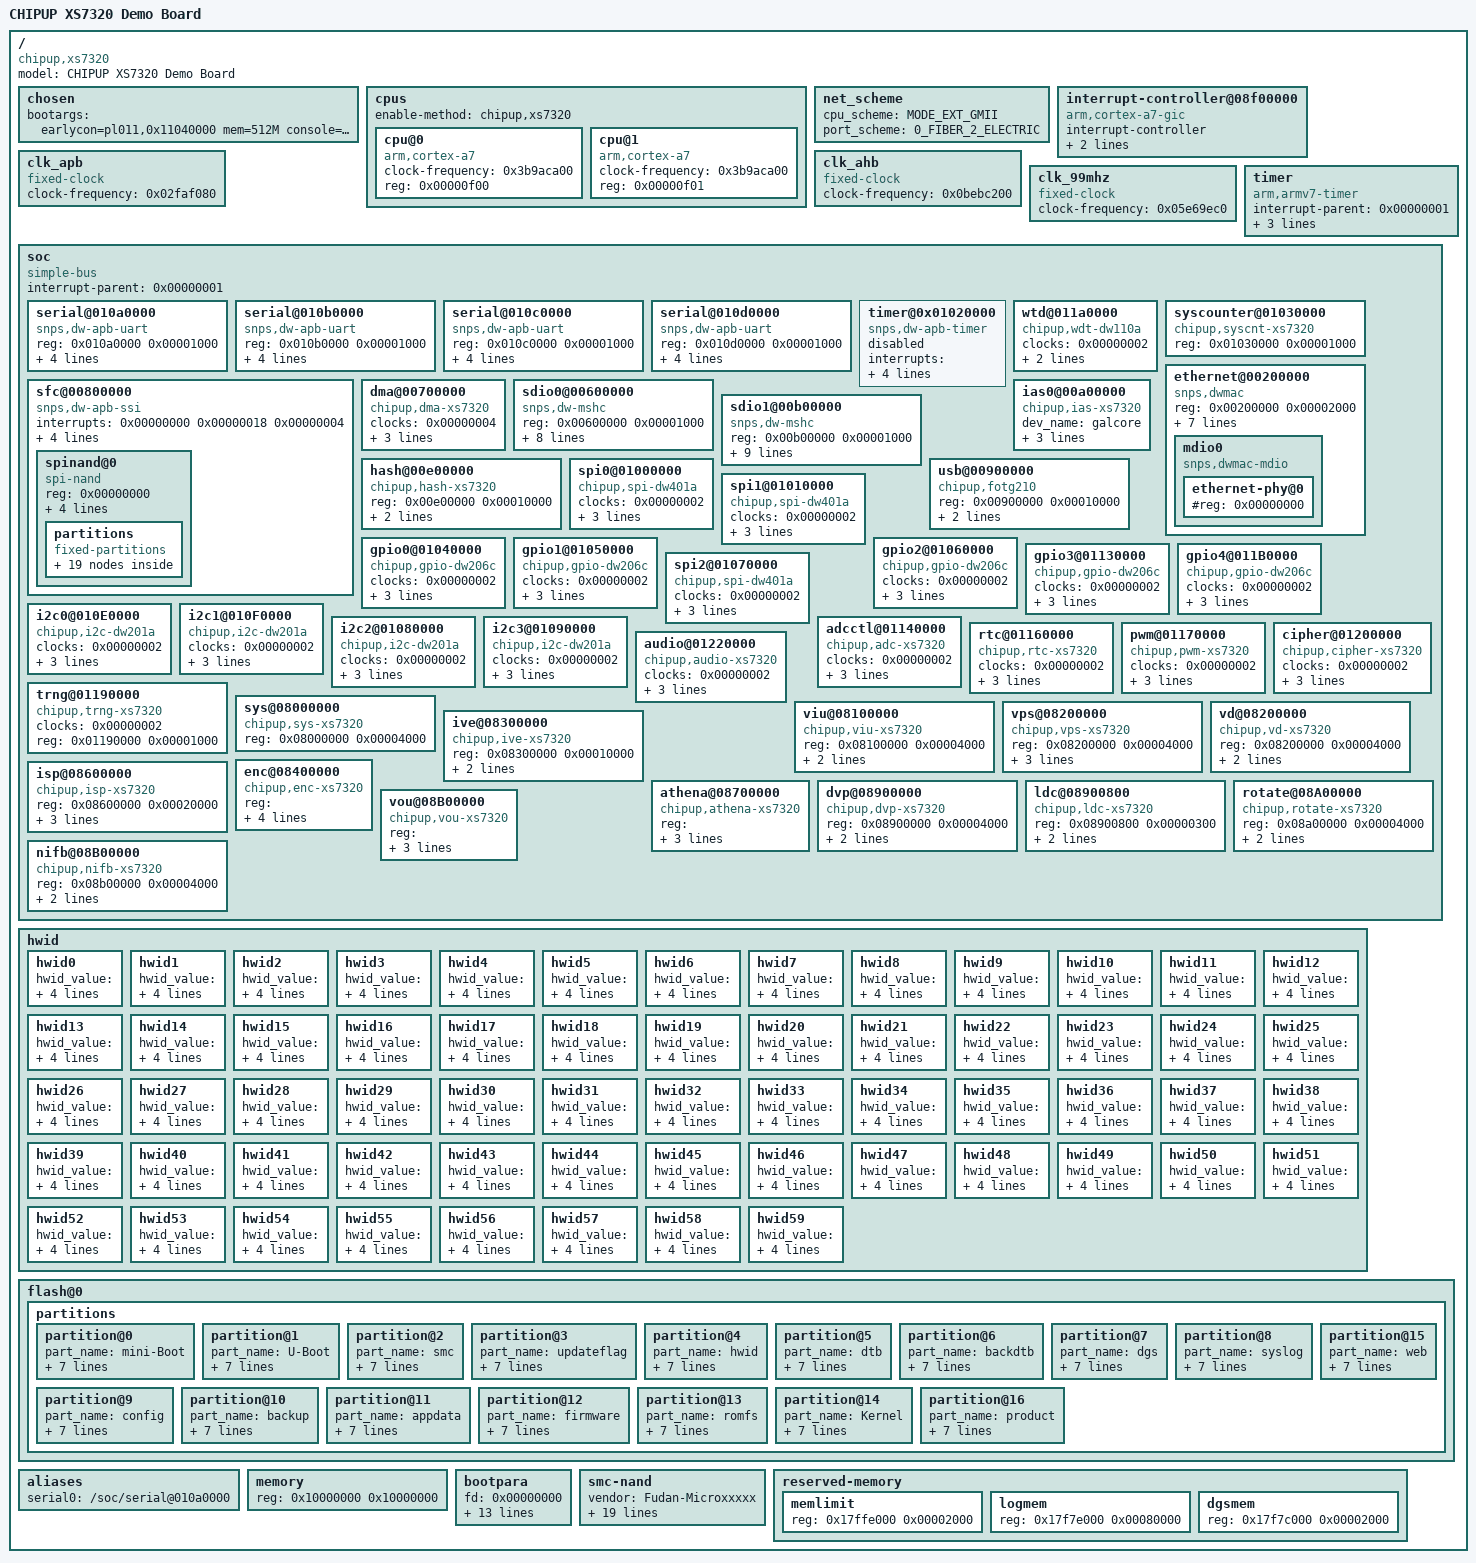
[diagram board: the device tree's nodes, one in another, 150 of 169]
/dts-v1/;
// magic:		0xd00dfeed
// totalsize:		0x86c5 (34501)
// off_dt_struct:	0x38
// off_dt_strings:	0x8318
// off_mem_rsvmap:	0x28
// version:		17
// last_comp_version:	16
// boot_cpuid_phys:	0x0
// size_dt_strings:	0x3ad
// size_dt_struct:	0x82e0

/ {
    #address-cells = <0x00000001>;
    #size-cells = <0x00000001>;
    model = "CHIPUP XS7320 Demo Board";
    compatible = "chipup,xs7320";
    chosen {
        bootargs = "earlycon=pl011,0x11040000 mem=512M console=ttyAMA0,115200 clk_ignore_unused initrd=0x00000000,0x00000000 root=/dev/mtdblock2 rootfstype=yaffs2 rw mtdparts=hinand:1M(boot),9M(kernel),32M(rootfs),1M(this_bootargs_string_is_reserved_for_bootargs_form_uboot!!!_it_must_be_longer_than_bootargs_form_uboot!!!_this_bootargs_string_is_reserved_for_bootargs_form_uboot!!!_it_must_be_longer_than_bootargs_form_uboot!!!_this_bootargs_string_is_reserved_for_bootargs_form_uboot!!!_it_must_be_longer_than_bootargs_form_uboot!!!_this_bootargs_string_is_reserved_for_bootargs_form_uboot!!!_it_must_be_longer_than_bootargs_form_uboot!!!_this_bootargs_string_is_reserved_for_bootargs_form_uboot!!!_it_must_be_longer_than_bootargs_form_uboot!!!)";
    };
    cpus {
        #address-cells = <0x00000001>;
        #size-cells = <0x00000000>;
        enable-method = "chipup,xs7320";
        cpu@0 {
            device_type = "cpu";
            compatible = "arm,cortex-a7";
            clock-frequency = <0x3b9aca00>;
            reg = <0x00000f00>;
        };
        cpu@1 {
            device_type = "cpu";
            compatible = "arm,cortex-a7";
            clock-frequency = <0x3b9aca00>;
            reg = <0x00000f01>;
        };
    };
    net_scheme {
        cpu_scheme = "MODE_EXT_GMII";
        port_scheme = "0_FIBER_2_ELECTRIC";
    };
    interrupt-controller@08f00000 {
        compatible = "arm,cortex-a7-gic";
        #interrupt-cells = <0x00000003>;
        interrupt-controller;
        reg = <0x08f01000 0x00001000 0x08f02000 0x00001000>;
        phandle = <0x00000001>;
    };
    clk_apb {
        compatible = "fixed-clock";
        #clock-cells = <0x00000000>;
        clock-frequency = <0x02faf080>;
        phandle = <0x00000002>;
    };
    clk_ahb {
        compatible = "fixed-clock";
        #clock-cells = <0x00000000>;
        clock-frequency = <0x0bebc200>;
        phandle = <0x00000004>;
    };
    clk_99mhz {
        compatible = "fixed-clock";
        #clock-cells = <0x00000000>;
        clock-frequency = <0x05e69ec0>;
        phandle = <0x00000005>;
    };
    timer {
        compatible = "arm,armv7-timer";
        interrupt-parent = <0x00000001>;
        clock-frequency = <0x016e3600>;
        arm,cpu-registers-not-fw-configured;
        interrupts = <0x00000001 0x0000000d 0x00000004>;
        status = "okay";
    };
    soc {
        #address-cells = <0x00000001>;
        #size-cells = <0x00000001>;
        compatible = "simple-bus";
        interrupt-parent = <0x00000001>;
        ranges;
        serial@010a0000 {
            compatible = "snps,dw-apb-uart";
            reg = <0x010a0000 0x00001000>;
            interrupts = <0x00000000 0x0000000c 0x00000004>;
            clocks = <0x00000002>;
            clock-names = "apb_pclk";
            reg-shift = <0x00000002>;
            reg-io-width = <0x00000004>;
            status = "okay";
        };
        serial@010b0000 {
            compatible = "snps,dw-apb-uart";
            reg = <0x010b0000 0x00001000>;
            interrupts = <0x00000000 0x0000000d 0x00000004>;
            clocks = <0x00000002>;
            clock-names = "apb_pclk";
            reg-shift = <0x00000002>;
            reg-io-width = <0x00000004>;
            status = "okay";
        };
        serial@010c0000 {
            compatible = "snps,dw-apb-uart";
            reg = <0x010c0000 0x00001000>;
            interrupts = <0x00000000 0x0000000e 0x00000004>;
            clocks = <0x00000002>;
            clock-names = "apb_pclk";
            reg-shift = <0x00000002>;
            reg-io-width = <0x00000004>;
            status = "okay";
        };
        serial@010d0000 {
            compatible = "snps,dw-apb-uart";
            reg = <0x010d0000 0x00001000>;
            interrupts = <0x00000000 0x0000000a 0x00000004>;
            clocks = <0x00000002>;
            clock-names = "apb_pclk";
            reg-shift = <0x00000002>;
            reg-io-width = <0x00000004>;
            status = "okay";
        };
        timer@0x01020000 {
            compatible = "snps,dw-apb-timer";
            interrupts = <0x00000000 0x00000001 0x00000004 0x00000000 0x00000002 0x00000004 0x00000000 0x00000003 0x00000004 0x00000000 0x00000004 0x00000004>;
            reg = <0x01020000 0x00001000>;
            clocks = <0x00000002>;
            clock-names = "apb_pclk";
            clock-frequency = <0x02faf080>;
            status = "disable";
        };
        wtd@011a0000 {
            compatible = "chipup,wdt-dw110a";
            clocks = <0x00000002>;
            reg = <0x011a0000 0x00001000>;
            interrupts = <0x00000000 0x00000027 0x00000004>;
        };
        syscounter@01030000 {
            compatible = "chipup,syscnt-xs7320";
            reg = <0x01030000 0x00001000>;
        };
        sfc@00800000 {
            compatible = "snps,dw-apb-ssi";
            interrupts = <0x00000000 0x00000018 0x00000004>;
            reg = <0x00800000 0x00010000>;
            reg-io-width = <0x00000004>;
            num-cs = <0x00000001>;
            clocks = <0x00000004>;
            #address-cells = <0x00000001>;
            #size-cells = <0x00000000>;
            status = "okay";
            spinand@0 {
                compatible = "spi-nand";
                reg = <0x00000000>;
                spi-max-frequency = <0x02faf080>;
                max-fifo-len = <0x00000080>;
                spi-rx-bus-width = <0x00000004>;
                spi-tx-bus-width = <0x00000001>;
                partitions {
                    compatible = "fixed-partitions";
                    #address-cells = <0x00000001>;
                    #size-cells = <0x00000001>;
                    partition@0 {
                        label = "mini-Boot";
                        reg = <0x00000000 0x00100000>;
                    };
                    partition@100000 {
                        label = "U-Boot";
                        reg = <0x00100000 0x00200000>;
                    };
                    partition@00300000 {
                        label = "updateflag";
                        reg = <0x00300000 0x00100000>;
                    };
                    partition@00400000 {
                        label = "hwid";
                        reg = <0x00400000 0x00100000>;
                    };
                    partition@00500000 {
                        label = "dtb";
                        reg = <0x00500000 0x00100000>;
                    };
                    partition@00600000 {
                        label = "backdtb";
                        reg = <0x00600000 0x00100000>;
                    };
                    partition@00700000 {
                        label = "dgs";
                        reg = <0x00700000 0x00100000>;
                    };
                    partition@00800000 {
                        label = "syslog";
                        reg = <0x00800000 0x00400000>;
                    };
                    partition@00C00000 {
                        label = "config";
                        reg = <0x00c00000 0x00400000>;
                    };
                    partition@01000000 {
                        label = "backup";
                        reg = <0x01000000 0x00400000>;
                    };
                    partition@01400000 {
                        label = "appdata";
                        reg = <0x01400000 0x00600000>;
                    };
                    partition@01A00000 {
                        label = "firmware";
                        reg = <0x01a00000 0x00400000>;
                    };
                    partition@02200000 {
                        label = "romfs";
                        reg = <0x01e00000 0x01b00000>;
                    };
                    partition@03D00000 {
                        label = "Kernel";
                        reg = <0x03900000 0x00d00000>;
                    };
                    partition@04800000 {
                        label = "web";
                        reg = <0x04600000 0x00c00000>;
                    };
                    partition@05400000 {
                        label = "product";
                        reg = <0x05200000 0x00300000>;
                    };
                    partition@05700000 {
                        label = "backromfs";
                        reg = <0x05500000 0x01b00000>;
                    };
                    partition@07200000 {
                        label = "backkernel";
                        reg = <0x07000000 0x00d00000>;
                    };
                    partition@07D00000 {
                        label = "backproduct";
                        reg = <0x07d00000 0x00300000>;
                    };
                };
            };
        };
        ethernet@00200000 {
            compatible = "snps,dwmac";
            reg = <0x00200000 0x00002000>;
            interrupt-parent = <0x00000001>;
            interrupts = <0x00000000 0x0000001e 0x00000004>;
            interrupt-names = "macirq";
            clocks = <0x00000004>;
            clock-names = "ni-gmac";
            snps,pbl = <0x00000002>;
            snps,fixed-burst;
            phy-mode = "mii";
            phy-handle = <0x00000003>;
            mdio0 {
                #address-cells = <0x00000001>;
                #size-cells = <0x00000000>;
                compatible = "snps,dwmac-mdio";
                ethernet-phy@0 {
                    #reg = <0x00000000>;
                    phandle = <0x00000003>;
                };
            };
        };
        dma@00700000 {
            compatible = "chipup,dma-xs7320";
            clocks = <0x00000004>;
            reg = <0x00700000 0x00001000>;
            interrupts = <0x00000000 0x0000001d 0x00000004>;
            interrupt-parent = <0x00000001>;
        };
        sdio0@00600000 {
            compatible = "snps,dw-mshc";
            reg = <0x00600000 0x00001000>;
            interrupts = <0x00000000 0x00000014 0x00000004>;
            interrupt-parent = <0x00000001>;
            clocks = <0x00000005 0x00000005>;
            clock-names = "biu", "ciu";
            max-frequency = <0x02faf080>;
            non-removable = "true";
            cap-mmc-highspeed = "true";
            fifo-depth = <0x00000200>;
            bus-width = <0x00000008>;
        };
        ias0@00a00000 {
            compatible = "chipup,ias-xs7320";
            dev_name = "galcore";
            status = "okay";
            reg = <0x00a00000 0x00010000>;
            interrupts = <0x00000000 0x0000002a 0x00000004>;
            interrupt-parent = <0x00000001>;
        };
        sdio1@00b00000 {
            compatible = "snps,dw-mshc";
            reg = <0x00b00000 0x00001000>;
            interrupts = <0x00000000 0x00000015 0x00000004>;
            interrupt-parent = <0x00000001>;
            clocks = <0x00000005 0x00000005>;
            clock-names = "biu", "ciu";
            max-frequency = <0x02faf080>;
            broken-cd = "true";
            cap-sd-highspeed = "true";
            fifo-depth = <0x00000200>;
            bus-width = <0x00000004>;
            pwr-gpio = <0x00000065>;
        };
        hash@00e00000 {
            compatible = "chipup,hash-xs7320";
            reg = <0x00e00000 0x00010000>;
            interrupts = <0x00000000 0x0000002f 0x00000004>;
            interrupt-parent = <0x00000001>;
        };
        usb@00900000 {
            compatible = "chipup,fotg210";
            reg = <0x00900000 0x00010000>;
            interrupts = <0x00000000 0x00000019 0x00000004>;
            interrupt-parent = <0x00000001>;
        };
        spi0@01000000 {
            compatible = "chipup,spi-dw401a";
            clocks = <0x00000002>;
            reg = <0x01000000 0x00001000>;
            interrupts = <0x00000000 0x00000010 0x00000004>;
            interrupt-parent = <0x00000001>;
        };
        spi1@01010000 {
            compatible = "chipup,spi-dw401a";
            clocks = <0x00000002>;
            reg = <0x01010000 0x00001000>;
            interrupts = <0x00000000 0x00000011 0x00000004>;
            interrupt-parent = <0x00000001>;
        };
        gpio0@01040000 {
            compatible = "chipup,gpio-dw206c";
            clocks = <0x00000002>;
            reg = <0x01040000 0x00001000>;
            interrupts = <0x00000000 0x0000000f 0x00000004>;
            interrupt-parent = <0x00000001>;
        };
        gpio1@01050000 {
            compatible = "chipup,gpio-dw206c";
            clocks = <0x00000002>;
            reg = <0x01050000 0x00001000>;
            interrupts = <0x00000000 0x00000013 0x00000004>;
            interrupt-parent = <0x00000001>;
        };
        gpio2@01060000 {
            compatible = "chipup,gpio-dw206c";
            clocks = <0x00000002>;
            reg = <0x01060000 0x00001000>;
            interrupts = <0x00000000 0x00000006 0x00000004>;
            interrupt-parent = <0x00000001>;
        };
        gpio3@01130000 {
            compatible = "chipup,gpio-dw206c";
            clocks = <0x00000002>;
            reg = <0x01130000 0x00001000>;
            interrupts = <0x00000000 0x00000034 0x00000004>;
            interrupt-parent = <0x00000001>;
        };
        gpio4@011B0000 {
            compatible = "chipup,gpio-dw206c";
            clocks = <0x00000002>;
            reg = <0x011b0000 0x00001000>;
            interrupts = <0x00000000 0x0000003d 0x00000004>;
            interrupt-parent = <0x00000001>;
        };
        spi2@01070000 {
            compatible = "chipup,spi-dw401a";
            clocks = <0x00000002>;
            reg = <0x01070000 0x00001000>;
            interrupts = <0x00000000 0x00000016 0x00000004>;
            interrupt-parent = <0x00000001>;
        };
        i2c0@010E0000 {
            compatible = "chipup,i2c-dw201a";
            clocks = <0x00000002>;
            reg = <0x010e0000 0x00001000>;
            interrupts = <0x00000000 0x00000007 0x00000004>;
            interrupt-parent = <0x00000001>;
        };
        i2c1@010F0000 {
            compatible = "chipup,i2c-dw201a";
            clocks = <0x00000002>;
            reg = <0x010f0000 0x00001000>;
            interrupts = <0x00000000 0x00000008 0x00000004>;
            interrupt-parent = <0x00000001>;
        };
        i2c2@01080000 {
            compatible = "chipup,i2c-dw201a";
            clocks = <0x00000002>;
            reg = <0x01080000 0x00001000>;
            interrupts = <0x00000000 0x00000009 0x00000004>;
            interrupt-parent = <0x00000001>;
        };
        i2c3@01090000 {
            compatible = "chipup,i2c-dw201a";
            clocks = <0x00000002>;
            reg = <0x01090000 0x00001000>;
            interrupts = <0x00000000 0x0000000b 0x00000004>;
            interrupt-parent = <0x00000001>;
        };
        adcctl@01140000 {
            compatible = "chipup,adc-xs7320";
            clocks = <0x00000002>;
            reg = <0x01140000 0x00001000>;
            interrupts = <0x00000000 0x0000001a 0x00000004>;
            interrupt-parent = <0x00000001>;
        };
        rtc@01160000 {
            compatible = "chipup,rtc-xs7320";
            clocks = <0x00000002>;
            reg = <0x01160000 0x00001000>;
            interrupts = <0x00000000 0x00000017 0x00000004>;
            interrupt-parent = <0x00000001>;
        };
        pwm@01170000 {
            compatible = "chipup,pwm-xs7320";
            clocks = <0x00000002>;
            reg = <0x01170000 0x00001000>;
            interrupts = <0x00000000 0x00000012 0x00000004>;
            interrupt-parent = <0x00000001>;
        };
        trng@01190000 {
            compatible = "chipup,trng-xs7320";
            clocks = <0x00000002>;
            reg = <0x01190000 0x00001000>;
        };
        cipher@01200000 {
            compatible = "chipup,cipher-xs7320";
            clocks = <0x00000002>;
            reg = <0x01200000 0x00001000>;
            interrupts = <0x00000000 0x0000002c 0x00000004>;
            interrupt-parent = <0x00000001>;
        };
        audio@01220000 {
            compatible = "chipup,audio-xs7320";
            clocks = <0x00000002>;
            reg = <0x01220000 0x00001000>;
            interrupts = <0x00000000 0x0000001c 0x00000004>;
            interrupt-parent = <0x00000001>;
        };
        sys@08000000 {
            compatible = "chipup,sys-xs7320";
            reg = <0x08000000 0x00004000>;
        };
        viu@08100000 {
            compatible = "chipup,viu-xs7320";
            reg = <0x08100000 0x00004000>;
            interrupts = <0x00000000 0x00000035 0x00000004>;
            interrupt-parent = <0x00000001>;
        };
        vps@08200000 {
            compatible = "chipup,vps-xs7320";
            reg = <0x08200000 0x00004000>;
            interrupts = <0x00000000 0x0000002e 0x00000004 0x00000000 0x00000036 0x00000004 0x00000000 0x00000037 0x00000004 0x00000000 0x00000039 0x00000004>;
            interrupt-parent = <0x00000001>;
        };
        vd@08200000 {
            compatible = "chipup,vd-xs7320";
            reg = <0x08200000 0x00004000>;
            interrupts = <0x00000000 0x0000002b 0x00000004>;
            interrupt-parent = <0x00000001>;
        };
        ive@08300000 {
            compatible = "chipup,ive-xs7320";
            status = "okay";
            reg = <0x08300000 0x00010000>;
            interrupts = <0x00000000 0x00000038 0x00000004>;
            interrupt-parent = <0x00000001>;
        };
        enc@08400000 {
            compatible = "chipup,enc-xs7320";
            reg = <0x08400000 0x00010000 0x08500000 0x00010000>;
            interrupts = <0x00000000 0x00000025 0x00000004 0x00000000 0x00000026 0x00000004 0x00000000 0x00000029 0x00000004 0x00000000 0x00000000 0x00000004>;
            interrupt-parent = <0x00000001>;
        };
        isp@08600000 {
            compatible = "chipup,isp-xs7320";
            reg = <0x08600000 0x00020000>;
            interrupts = <0x00000000 0x00000020 0x00000004 0x00000000 0x00000021 0x00000004 0x00000000 0x00000022 0x00000004 0x00000000 0x00000023 0x00000004 0x00000000 0x00000024 0x00000004 0x00000000 0x0000002d 0x00000004>;
            interrupt-parent = <0x00000001>;
        };
        athena@08700000 {
            compatible = "chipup,athena-xs7320";
            reg = <0x08700000 0x00020000 0x08000000 0x000000b8>;
            interrupts = <0x00000000 0x00000031 0x00000004>;
            interrupt-parent = <0x00000001>;
        };
        dvp@08900000 {
            compatible = "chipup,dvp-xs7320";
            reg = <0x08900000 0x00004000>;
            interrupts = <0x00000000 0x0000001f 0x00000004>;
            interrupt-parent = <0x00000001>;
        };
        ldc@08900800 {
            compatible = "chipup,ldc-xs7320";
            reg = <0x08900800 0x00000300>;
            interrupts = <0x00000000 0x0000003f 0x00000004>;
            interrupt-parent = <0x00000001>;
        };
        rotate@08A00000 {
            compatible = "chipup,rotate-xs7320";
            reg = <0x08a00000 0x00004000>;
            interrupts = <0x00000000 0x00000032 0x00000004>;
            interrupt-parent = <0x00000001>;
        };
        vou@08B00000 {
            compatible = "chipup,vou-xs7320";
            reg = <0x08b00000 0x00004000 0x08500000 0x00010000>;
            interrupts = <0x00000000 0x0000001b 0x00000004>;
            interrupt-parent = <0x00000001>;
        };
        nifb@08B00000 {
            compatible = "chipup,nifb-xs7320";
            reg = <0x08b00000 0x00004000>;
            interrupts = <0x00000000 0x0000001b 0x00000004>;
            interrupt-parent = <0x00000001>;
        };
    };
    hwid {
        hwid0 {
            hwid_value = "IPC-HFE4243S-AS-LED:01:02:02:B4:57:00:01:10:01:01:04:3E8:03:00:00:00:00:01:00:00:200";
            bootargs = "mem=480M reserved-memory=227M@0x1FD00000 vmalloc=512M gpu-memory=032M@0x2E000000 console=ttyS0,115200 root=/dev/mtdblock12 rootfstype=squashfs init=/linuxrc";
            boot_reginfo = "boot_register_node1";
        };
        hwid1 {
            hwid_value = "IPC-HFW4443DT-SA-0210B:01:02:00:C8:57:00:01:10:01:00:04:3E8:00:00:00:00:00:01:00:00:200";
            bootargs = "mem=500M reserved-memory=250M@0x1FA00000 vmalloc=768M gpu-memory=012M@0x2F400000 console=ttyS0,115200 root=/dev/mtdblock12 rootfstype=squashfs init=/linuxrc";
            boot_reginfo = "boot_register_node1";
        };
        hwid2 {
            hwid_value = "IPC-HFW4443T-AS-0210B:01:02:00:C8:57:00:01:10:03:01:04:3E8:08:00:00:00:00:01:00:00:200";
            bootargs = "mem=500M reserved-memory=250M@0x1FA00000 vmalloc=768M gpu-memory=012M@0x2F400000 console=ttyS0,115200 root=/dev/mtdblock12 rootfstype=squashfs init=/linuxrc";
            boot_reginfo = "boot_register_node1";
        };
        hwid3 {
            hwid_value = "IPC-HFW5443DT-SA-0210B:01:02:00:C8:57:00:01:10:01:00:04:3E8:00:00:00:00:00:01:00:00:200";
            bootargs = "mem=500M reserved-memory=250M@0x1FA00000 vmalloc=768M gpu-memory=012M@0x2F400000 console=ttyS0,115200 root=/dev/mtdblock12 rootfstype=squashfs init=/linuxrc";
            boot_reginfo = "boot_register_node1";
        };
        hwid4 {
            hwid_value = "IPC-HFW5443T-AS-0210B:01:02:00:C8:57:00:01:10:03:01:04:3E8:08:00:00:00:00:01:00:00:200";
            bootargs = "mem=500M reserved-memory=250M@0x1FA00000 vmalloc=768M gpu-memory=012M@0x2F400000 console=ttyS0,115200 root=/dev/mtdblock12 rootfstype=squashfs init=/linuxrc";
            boot_reginfo = "boot_register_node1";
        };
        hwid5 {
            hwid_value = "IPC-HDBW4443DR-SA-0210B:01:02:00:C8:57:00:01:10:01:00:04:3E8:00:00:00:00:00:01:00:00:200";
            bootargs = "mem=500M reserved-memory=250M@0x1FA00000 vmalloc=768M gpu-memory=012M@0x2F400000 console=ttyS0,115200 root=/dev/mtdblock12 rootfstype=squashfs init=/linuxrc";
            boot_reginfo = "boot_register_node1";
        };
        hwid6 {
            hwid_value = "IPC-HDBW4443R-AS-0210B:01:02:00:C8:57:00:01:10:03:01:04:3E8:08:00:00:00:00:01:00:00:200";
            bootargs = "mem=500M reserved-memory=250M@0x1FA00000 vmalloc=768M gpu-memory=012M@0x2F400000 console=ttyS0,115200 root=/dev/mtdblock12 rootfstype=squashfs init=/linuxrc";
            boot_reginfo = "boot_register_node1";
        };
        hwid7 {
            hwid_value = "IPC-HDBW5443DR-SA-0210B:01:02:00:C8:57:00:01:10:01:00:04:3E8:00:00:00:00:00:01:00:00:200";
            bootargs = "mem=500M reserved-memory=250M@0x1FA00000 vmalloc=768M gpu-memory=012M@0x2F400000 console=ttyS0,115200 root=/dev/mtdblock12 rootfstype=squashfs init=/linuxrc";
            boot_reginfo = "boot_register_node1";
        };
        hwid8 {
            hwid_value = "IPC-HDBW5443R-AS-0210B:01:02:00:C8:57:00:01:10:03:01:04:3E8:08:00:00:00:00:01:00:00:200";
            bootargs = "mem=500M reserved-memory=250M@0x1FA00000 vmalloc=768M gpu-memory=012M@0x2F400000 console=ttyS0,115200 root=/dev/mtdblock12 rootfstype=squashfs init=/linuxrc";
            boot_reginfo = "boot_register_node1";
        };
        hwid9 {
            hwid_value = "IPC-HFE4443S-AS-LED:01:02:02:CE:57:00:01:10:01:01:04:3E8:03:00:00:00:00:01:00:00:200";
            bootargs = "mem=500M reserved-memory=250M@0x1FA00000 vmalloc=768M gpu-memory=012M@0x2F400000 console=ttyS0,115200 root=/dev/mtdblock12 rootfstype=squashfs init=/linuxrc";
            boot_reginfo = "boot_register_node1";
        };
        hwid10 {
            hwid_value = "IPC-HFW5243M1-YL-PV-SA:01:02:02:B4:57:00:01:10:01:01:04:3E8:00:00:00:00:00:01:00:00:200";
            bootargs = "mem=500M reserved-memory=250M@0x1FA00000 vmalloc=768M gpu-memory=012M@0x2F400000 console=ttyS0,115200 root=/dev/mtdblock12 rootfstype=squashfs init=/linuxrc";
            boot_reginfo = "boot_register_node1";
        };
        hwid11 {
            hwid_value = "IPC-HFW5243M1-YL-PV-AS:01:02:02:B4:57:00:01:10:03:03:04:3E8:08:00:00:00:00:01:00:00:200";
            bootargs = "mem=500M reserved-memory=250M@0x1FA00000 vmalloc=768M gpu-memory=012M@0x2F400000 console=ttyS0,115200 root=/dev/mtdblock12 rootfstype=squashfs init=/linuxrc";
            boot_reginfo = "boot_register_node1";
        };
        hwid12 {
            hwid_value = "IPC-HDBW5243R1-YL-PV-SA:01:02:04:B4:57:00:01:10:01:01:04:3E8:00:00:00:00:00:01:00:00:200";
            bootargs = "mem=500M reserved-memory=250M@0x1FA00000 vmalloc=768M gpu-memory=012M@0x2F400000 console=ttyS0,115200 root=/dev/mtdblock12 rootfstype=squashfs init=/linuxrc";
            boot_reginfo = "boot_register_node1";
        };
        hwid13 {
            hwid_value = "IPC-HDBW5243R1-YL-PV-AS:01:02:04:B4:57:00:01:10:03:03:04:3E8:08:00:00:00:00:01:00:00:200";
            bootargs = "mem=500M reserved-memory=250M@0x1FA00000 vmalloc=768M gpu-memory=012M@0x2F400000 console=ttyS0,115200 root=/dev/mtdblock12 rootfstype=squashfs init=/linuxrc";
            boot_reginfo = "boot_register_node1";
        };
        hwid14 {
            hwid_value = "IPC-HFW5243F1-ZYL-PV-AS-27135:01:02:00:B4:57:00:01:10:03:03:04:3E8:08:00:00:00:00:01:00:00:200";
            bootargs = "mem=500M reserved-memory=250M@0x1FA00000 vmalloc=768M gpu-memory=012M@0x2F400000 console=ttyS0,115200 root=/dev/mtdblock12 rootfstype=squashfs init=/linuxrc";
            boot_reginfo = "boot_register_node1";
        };
        hwid15 {
            hwid_value = "IPC-HFW5243F1-ZYL-PV-SA-27135:01:02:00:B4:57:00:01:10:01:01:04:3E8:00:00:00:00:00:01:00:00:200";
            bootargs = "mem=500M reserved-memory=250M@0x1FA00000 vmalloc=768M gpu-memory=012M@0x2F400000 console=ttyS0,115200 root=/dev/mtdblock12 rootfstype=squashfs init=/linuxrc";
            boot_reginfo = "boot_register_node1";
        };
        hwid16 {
            hwid_value = "IPC-HFW5243F1-ZYL-PV-SA-0624:01:02:00:B4:57:00:01:10:01:01:04:3E8:00:00:00:00:00:01:00:00:200";
            bootargs = "mem=500M reserved-memory=250M@0x1FA00000 vmalloc=768M gpu-memory=012M@0x2F400000 console=ttyS0,115200 root=/dev/mtdblock12 rootfstype=squashfs init=/linuxrc";
            boot_reginfo = "boot_register_node1";
        };
        hwid17 {
            hwid_value = "IPC-HFW5243F1-ZYL-PV-AS-0624:01:02:00:B4:57:00:01:10:03:03:04:3E8:08:00:00:00:00:01:00:00:200";
            bootargs = "mem=500M reserved-memory=250M@0x1FA00000 vmalloc=768M gpu-memory=012M@0x2F400000 console=ttyS0,115200 root=/dev/mtdblock12 rootfstype=squashfs init=/linuxrc";
            boot_reginfo = "boot_register_node1";
        };
        hwid18 {
            hwid_value = "IPC-HDBW5243R1-ZYL-PV-AS-27135:01:02:00:B4:57:00:01:10:03:03:04:3E8:08:00:00:00:00:01:00:00:200";
            bootargs = "mem=500M reserved-memory=250M@0x1FA00000 vmalloc=768M gpu-memory=012M@0x2F400000 console=ttyS0,115200 root=/dev/mtdblock12 rootfstype=squashfs init=/linuxrc";
            boot_reginfo = "boot_register_node1";
        };
        hwid19 {
            hwid_value = "IPC-HDBW5243R1-ZYL-PV-SA-27135:01:02:00:B4:57:00:01:10:01:01:04:3E8:00:00:00:00:00:01:00:00:200";
            bootargs = "mem=500M reserved-memory=250M@0x1FA00000 vmalloc=768M gpu-memory=012M@0x2F400000 console=ttyS0,115200 root=/dev/mtdblock12 rootfstype=squashfs init=/linuxrc";
            boot_reginfo = "boot_register_node1";
        };
        hwid20 {
            hwid_value = "IPC-HDBW5243R1-ZYL-PV-SA-0624:01:02:00:B4:57:00:01:10:01:01:04:3E8:00:00:00:00:00:01:00:00:200";
            bootargs = "mem=500M reserved-memory=250M@0x1FA00000 vmalloc=768M gpu-memory=012M@0x2F400000 console=ttyS0,115200 root=/dev/mtdblock12 rootfstype=squashfs init=/linuxrc";
            boot_reginfo = "boot_register_node1";
        };
        hwid21 {
            hwid_value = "IPC-HDBW5243R1-ZYL-PV-AS-0624:01:02:00:B4:57:00:01:10:03:03:04:3E8:08:00:00:00:00:01:00:00:200";
            bootargs = "mem=500M reserved-memory=250M@0x1FA00000 vmalloc=768M gpu-memory=012M@0x2F400000 console=ttyS0,115200 root=/dev/mtdblock12 rootfstype=squashfs init=/linuxrc";
            boot_reginfo = "boot_register_node1";
        };
        hwid22 {
            hwid_value = "IPC-PFW5849-A180-E2-ST:01:02:02:86:56:00:01:10:00:00:04:3E8:00:00:00:00:00:01:00:00:400";
            bootargs = "mem=1014M reserved-memory=652M@0x26A00000 vmalloc=768M gpu-memory=010M@0x4F600000 console=ttyS0,115200 root=/dev/mtdblock12 rootfstype=squashfs init=/linuxrc";
            boot_reginfo = "boot_register_node1";
        };
        hwid23 {
            hwid_value = "IPC-PFW5849-A180-E2-AST:01:02:02:86:56:00:01:10:03:03:04:3E8:08:00:00:04:00:01:00:00:400";
            bootargs = "mem=1014M reserved-memory=652M@0x26A00000 vmalloc=768M gpu-memory=010M@0x4F600000 console=ttyS0,115200 root=/dev/mtdblock12 rootfstype=squashfs init=/linuxrc";
            boot_reginfo = "boot_register_node1";
        };
        hwid24 {
            hwid_value = "IPC-PFW4849-A180-E2-AST:01:02:02:86:56:00:01:10:03:03:04:3E8:08:00:00:04:00:01:00:00:400";
            bootargs = "mem=1014M reserved-memory=652M@0x26A00000 vmalloc=768M gpu-memory=010M@0x4F600000 console=ttyS0,115200 root=/dev/mtdblock12 rootfstype=squashfs init=/linuxrc";
            boot_reginfo = "boot_register_node1";
        };
        hwid25 {
            hwid_value = "IPC-PDW5849-A180-E2-AST:01:02:02:86:56:00:01:10:03:03:04:3E8:08:00:00:04:00:01:00:00:400";
            bootargs = "mem=1014M reserved-memory=652M@0x26A00000 vmalloc=768M gpu-memory=010M@0x4F600000 console=ttyS0,115200 root=/dev/mtdblock12 rootfstype=squashfs init=/linuxrc";
            boot_reginfo = "boot_register_node1";
        };
        hwid26 {
            hwid_value = "IPC-PDW4849-A180-E2-AST:01:02:02:86:56:00:01:10:03:03:04:3E8:08:00:00:04:00:01:00:00:400";
            bootargs = "mem=1014M reserved-memory=652M@0x26A00000 vmalloc=768M gpu-memory=010M@0x4F600000 console=ttyS0,115200 root=/dev/mtdblock12 rootfstype=squashfs init=/linuxrc";
            boot_reginfo = "boot_register_node1";
        };
        hwid27 {
            hwid_value = "IPC-PFW5849P-A180-E2-ASTE:01:02:02:86:56:00:01:10:03:03:04:3E8:08:00:00:04:00:01:00:00:400";
            bootargs = "mem=1014M reserved-memory=652M@0x26A00000 vmalloc=768M gpu-memory=010M@0x4F600000 console=ttyS0,115200 root=/dev/mtdblock12 rootfstype=squashfs init=/linuxrc";
            boot_reginfo = "boot_register_node1";
        };
        hwid28 {
            hwid_value = "IPC-PFW5849P-A180-E2-ASTE-M:01:02:02:86:56:00:01:10:03:03:04:3E8:03:00:00:00:00:01:00:00:400";
            bootargs = "mem=1014M reserved-memory=652M@0x26A00000 vmalloc=768M gpu-memory=010M@0x4F600000 console=ttyS0,115200 root=/dev/mtdblock12 rootfstype=squashfs init=/linuxrc";
            boot_reginfo = "boot_register_node1";
        };
        hwid29 {
            hwid_value = "IPC-HFW5449F1-ZAST-G4G-DGH:01:02:02:86:57:00:01:10:03:03:04:3E8:09:00:00:00:00:01:00:00:400";
            bootargs = "mem=992M reserved-memory=400M@0x35000000 vmalloc=768M gpu-memory=032M@0x4E000000 console=ttyS0,115200 root=/dev/mtdblock12 rootfstype=squashfs init=/linuxrc";
            boot_reginfo = "boot_register_node1";
        };
        hwid30 {
            hwid_value = "IPC-PFW5449-A180-E2-ST-0360B:01:02:00:B4:57:00:01:10:01:01:04:3E8:00:00:00:00:00:01:00:00:400";
            bootargs = "mem=992M reserved-memory=670M@0x24200000 vmalloc=768M gpu-memory=032M@0x4E000000 console=ttyS0,115200 root=/dev/mtdblock12 rootfstype=squashfs init=/linuxrc";
            boot_reginfo = "boot_register_node1";
        };
        hwid31 {
            hwid_value = "IPC-PFW5449-A180-E2-AST-0360B:01:02:00:B4:57:00:01:10:03:03:04:3E8:08:00:00:04:00:01:00:00:400";
            bootargs = "mem=992M reserved-memory=670M@0x24200000 vmalloc=768M gpu-memory=032M@0x4E000000 console=ttyS0,115200 root=/dev/mtdblock12 rootfstype=squashfs init=/linuxrc";
            boot_reginfo = "boot_register_node1";
        };
        hwid32 {
            hwid_value = "IPC-PDW5449-A180-E2-AST-0360B:01:02:00:B4:57:00:01:10:03:03:04:3E8:08:00:00:04:00:01:00:00:400";
            bootargs = "mem=992M reserved-memory=670M@0x24200000 vmalloc=768M gpu-memory=032M@0x4E000000 console=ttyS0,115200 root=/dev/mtdblock12 rootfstype=squashfs init=/linuxrc";
            boot_reginfo = "boot_register_node1";
        };
        hwid33 {
            hwid_value = "IPC-PFW4449-A180-E2-AST-0360B:01:02:00:B4:57:00:01:10:03:03:04:3E8:08:00:00:04:00:01:00:00:400";
            bootargs = "mem=992M reserved-memory=670M@0x24200000 vmalloc=768M gpu-memory=032M@0x4E000000 console=ttyS0,115200 root=/dev/mtdblock12 rootfstype=squashfs init=/linuxrc";
            boot_reginfo = "boot_register_node1";
        };
        hwid34 {
            hwid_value = "IPC-PDW4449-A180-E2-AST-0360B:01:02:00:B4:57:00:01:10:03:03:04:3E8:08:00:00:04:00:01:00:00:400";
            bootargs = "mem=992M reserved-memory=670M@0x24200000 vmalloc=768M gpu-memory=032M@0x4E000000 console=ttyS0,115200 root=/dev/mtdblock12 rootfstype=squashfs init=/linuxrc";
            boot_reginfo = "boot_register_node1";
        };
        hwid35 {
            hwid_value = "IPC-HFE4843S-AS-LED:01:02:02:8F:56:00:01:10:01:01:04:3E8:03:00:00:00:00:01:00:00:400";
            bootargs = "mem=992M reserved-memory=670M@0x24200000 vmalloc=768M gpu-memory=032M@0x4E000000 console=ttyS0,115200 root=/dev/mtdblock12 rootfstype=squashfs init=/linuxrc";
            boot_reginfo = "boot_register_node1";
        };
        hwid36 {
            hwid_value = "IPC-HDW5849HP-ASE-LED:01:02:00:D1:56:00:01:14:07:01:04:3E8:03:00:00:00:00:01:00:00:400";
            bootargs = "mem=992M reserved-memory=492M@0x2F400000 vmalloc=768M gpu-memory=032M@0x4E000000 console=ttyS0,115200 root=/dev/mtdblock12 rootfstype=squashfs init=/linuxrc";
            boot_reginfo = "boot_register_node1";
        };
        hwid37 {
            hwid_value = "IPC-HDW5849H-YL-AS-LED:01:02:00:D1:56:00:01:14:07:01:04:3E8:08:00:00:00:00:01:00:00:400";
            bootargs = "mem=992M reserved-memory=492M@0x2F400000 vmalloc=768M gpu-memory=032M@0x4E000000 console=ttyS0,115200 root=/dev/mtdblock12 rootfstype=squashfs init=/linuxrc";
            boot_reginfo = "boot_register_node1";
        };
        hwid38 {
            hwid_value = "IPC-HFW5849F1-YL-PV-AS-LED:01:02:00:D1:56:00:01:14:07:03:04:3E8:08:00:00:00:00:01:00:00:400";
            bootargs = "mem=992M reserved-memory=492M@0x2F400000 vmalloc=768M gpu-memory=032M@0x4E000000 console=ttyS0,115200 root=/dev/mtdblock12 rootfstype=squashfs init=/linuxrc";
            boot_reginfo = "boot_register_node1";
        };
        hwid39 {
            hwid_value = "IPC-HFW4849F1-PV-AS-LED:01:02:00:D1:56:00:01:14:07:03:04:3E8:08:00:00:00:00:01:00:00:400";
            bootargs = "mem=992M reserved-memory=492M@0x2F400000 vmalloc=768M gpu-memory=032M@0x4E000000 console=ttyS0,115200 root=/dev/mtdblock12 rootfstype=squashfs init=/linuxrc";
            boot_reginfo = "boot_register_node1";
        };
        hwid40 {
            hwid_value = "IPC-HDW4849H-AS-LED:01:02:00:D1:56:00:01:14:07:01:04:3E8:08:00:00:00:00:01:00:00:400";
            bootargs = "mem=992M reserved-memory=492M@0x2F400000 vmalloc=768M gpu-memory=032M@0x4E000000 console=ttyS0,115200 root=/dev/mtdblock12 rootfstype=squashfs init=/linuxrc";
            boot_reginfo = "boot_register_node1";
        };
        hwid41 {
            hwid_value = "IPC-HFW5443DM1-YL-PV-4G-AS:01:02:00:C8:57:00:01:10:03:03:04:3E8:08:00:00:00:00:01:00:00:400";
            bootargs = "mem=992M reserved-memory=492M@0x2F400000 vmalloc=768M gpu-memory=032M@0x4E000000 console=ttyS0,115200 root=/dev/mtdblock12 rootfstype=squashfs init=/linuxrc";
            boot_reginfo = "boot_register_node1";
        };
        hwid42 {
            hwid_value = "IPC-HFW5443F1-ZYL-PV-4G-27135:01:02:00:C8:57:00:01:10:03:03:04:3E8:09:00:00:00:00:01:00:00:400";
            bootargs = "mem=992M reserved-memory=492M@0x2F400000 vmalloc=768M gpu-memory=032M@0x4E000000 console=ttyS0,115200 root=/dev/mtdblock12 rootfstype=squashfs init=/linuxrc";
            boot_reginfo = "boot_register_node1";
        };
        hwid43 {
            hwid_value = "IPC-HFW5443F1-ZYL-PV-4G-0624:01:02:00:C8:57:00:01:10:03:03:04:3E8:09:00:00:00:00:01:00:00:400";
            bootargs = "mem=992M reserved-memory=492M@0x2F400000 vmalloc=768M gpu-memory=032M@0x4E000000 console=ttyS0,115200 root=/dev/mtdblock12 rootfstype=squashfs init=/linuxrc";
            boot_reginfo = "boot_register_node1";
        };
        hwid44 {
            hwid_value = "IPC-HFW5443M1-YL-PV-SA:01:02:02:C8:57:00:01:10:01:01:04:3E8:00:00:00:00:00:01:00:00:400";
            bootargs = "mem=992M reserved-memory=492M@0x2F400000 vmalloc=768M gpu-memory=032M@0x4E000000 console=ttyS0,115200 root=/dev/mtdblock12 rootfstype=squashfs init=/linuxrc";
            boot_reginfo = "boot_register_node1";
        };
        hwid45 {
            hwid_value = "IPC-HFW5443M1-YL-PV-AS:01:02:02:C8:57:00:01:10:03:03:04:3E8:08:00:00:00:00:01:00:00:400";
            bootargs = "mem=992M reserved-memory=492M@0x2F400000 vmalloc=768M gpu-memory=032M@0x4E000000 console=ttyS0,115200 root=/dev/mtdblock12 rootfstype=squashfs init=/linuxrc";
            boot_reginfo = "boot_register_node1";
        };
        hwid46 {
            hwid_value = "IPC-HDBW5443R1-YL-PV-SA:01:02:04:C8:57:00:01:10:01:01:04:3E8:00:00:00:00:00:01:00:00:400";
            bootargs = "mem=992M reserved-memory=492M@0x2F400000 vmalloc=768M gpu-memory=032M@0x4E000000 console=ttyS0,115200 root=/dev/mtdblock12 rootfstype=squashfs init=/linuxrc";
            boot_reginfo = "boot_register_node1";
        };
        hwid47 {
            hwid_value = "IPC-HDBW5443R1-YL-PV-AS:01:02:04:C8:57:00:01:10:03:03:04:3E8:08:00:00:00:00:01:00:00:400";
            bootargs = "mem=992M reserved-memory=492M@0x2F400000 vmalloc=768M gpu-memory=032M@0x4E000000 console=ttyS0,115200 root=/dev/mtdblock12 rootfstype=squashfs init=/linuxrc";
            boot_reginfo = "boot_register_node1";
        };
        hwid48 {
            hwid_value = "IPC-HDBW5443R1-YL-PV-AS-X:01:02:04:C8:57:00:01:10:03:03:04:3E8:08:00:02:04:00:01:00:00:400";
            bootargs = "mem=992M reserved-memory=492M@0x2F400000 vmalloc=768M gpu-memory=032M@0x4E000000 console=ttyS0,115200 root=/dev/mtdblock12 rootfstype=squashfs init=/linuxrc";
            boot_reginfo = "boot_register_node1";
        };
        hwid49 {
            hwid_value = "IPC-HFW5443M1-YL-PV-AS-X:01:02:04:C8:57:00:01:10:03:03:04:3E8:08:00:02:04:00:01:00:00:400";
            bootargs = "mem=992M reserved-memory=492M@0x2F400000 vmalloc=768M gpu-memory=032M@0x4E000000 console=ttyS0,115200 root=/dev/mtdblock12 rootfstype=squashfs init=/linuxrc";
            boot_reginfo = "boot_register_node1";
        };
        hwid50 {
            hwid_value = "IPC-HFW5443F1-ZYL-PV-SA-0624:01:02:00:C8:57:00:01:10:01:01:04:3E8:00:00:00:00:00:01:00:00:400";
            bootargs = "mem=992M reserved-memory=492M@0x2F400000 vmalloc=768M gpu-memory=032M@0x4E000000 console=ttyS0,115200 root=/dev/mtdblock12 rootfstype=squashfs init=/linuxrc";
            boot_reginfo = "boot_register_node1";
        };
        hwid51 {
            hwid_value = "IPC-HFW5443F1-ZYL-PV-AS-0624:01:02:00:C8:57:00:01:10:03:03:04:3E8:08:00:00:00:00:01:00:00:400";
            bootargs = "mem=992M reserved-memory=492M@0x2F400000 vmalloc=768M gpu-memory=032M@0x4E000000 console=ttyS0,115200 root=/dev/mtdblock12 rootfstype=squashfs init=/linuxrc";
            boot_reginfo = "boot_register_node1";
        };
        hwid52 {
            hwid_value = "IPC-HFW5443F1-ZYL-PV-AS-X-JM:01:02:00:C8:57:00:01:10:03:03:04:3E8:09:00:02:04:00:01:00:00:400";
            bootargs = "mem=992M reserved-memory=492M@0x2F400000 vmalloc=768M gpu-memory=032M@0x4E000000 console=ttyS0,115200 root=/dev/mtdblock12 rootfstype=squashfs init=/linuxrc";
            boot_reginfo = "boot_register_node1";
        };
        hwid53 {
            hwid_value = "IPC-HDBW5443R1-ZYL-PV-AS-27135:01:02:00:C8:57:00:01:10:03:03:04:3E8:08:00:00:00:00:01:00:00:400";
            bootargs = "mem=992M reserved-memory=492M@0x2F400000 vmalloc=768M gpu-memory=032M@0x4E000000 console=ttyS0,115200 root=/dev/mtdblock12 rootfstype=squashfs init=/linuxrc";
            boot_reginfo = "boot_register_node1";
        };
        hwid54 {
            hwid_value = "IPC-HDBW5443R1-ZYL-PV-SA-27135:01:02:00:C8:57:00:01:10:01:01:04:3E8:00:00:00:00:00:01:00:00:400";
            bootargs = "mem=992M reserved-memory=492M@0x2F400000 vmalloc=768M gpu-memory=032M@0x4E000000 console=ttyS0,115200 root=/dev/mtdblock12 rootfstype=squashfs init=/linuxrc";
            boot_reginfo = "boot_register_node1";
        };
        hwid55 {
            hwid_value = "IPC-HDBW5443R1-ZYL-PV-SA-0624:01:02:00:C8:57:00:01:10:01:01:04:3E8:00:00:00:00:00:01:00:00:400";
            bootargs = "mem=992M reserved-memory=492M@0x2F400000 vmalloc=768M gpu-memory=032M@0x4E000000 console=ttyS0,115200 root=/dev/mtdblock12 rootfstype=squashfs init=/linuxrc";
            boot_reginfo = "boot_register_node1";
        };
        hwid56 {
            hwid_value = "IPC-HDBW5443R1-ZYL-PV-AS-0624:01:02:00:C8:57:00:01:10:03:03:04:3E8:08:00:00:00:00:01:00:00:400";
            bootargs = "mem=992M reserved-memory=492M@0x2F400000 vmalloc=768M gpu-memory=032M@0x4E000000 console=ttyS0,115200 root=/dev/mtdblock12 rootfstype=squashfs init=/linuxrc";
            boot_reginfo = "boot_register_node1";
        };
        hwid57 {
            hwid_value = "IPC-HDBW5443R1-ZYL-PV-AS-X-JM:01:02:00:C8:57:00:01:10:03:03:04:3E8:09:00:02:04:00:01:00:00:400";
            bootargs = "mem=992M reserved-memory=492M@0x2F400000 vmalloc=768M gpu-memory=032M@0x4E000000 console=ttyS0,115200 root=/dev/mtdblock12 rootfstype=squashfs init=/linuxrc";
            boot_reginfo = "boot_register_node1";
        };
        hwid58 {
            hwid_value = "IPC-HFW5443F1-ZYL-PV-SA-27135:01:02:00:C8:57:00:01:10:01:01:04:3E8:00:00:00:00:00:01:00:00:400";
            bootargs = "mem=992M reserved-memory=492M@0x2F400000 vmalloc=768M gpu-memory=032M@0x4E000000 console=ttyS0,115200 root=/dev/mtdblock12 rootfstype=squashfs init=/linuxrc";
            boot_reginfo = "boot_register_node1";
        };
        hwid59 {
            hwid_value = "IPC-HFW5443F1-ZYL-PV-AS-27135:01:02:00:C8:57:00:01:10:03:03:04:3E8:08:00:00:00:00:01:00:00:400";
            bootargs = "mem=992M reserved-memory=492M@0x2F400000 vmalloc=768M gpu-memory=032M@0x4E000000 console=ttyS0,115200 root=/dev/mtdblock12 rootfstype=squashfs init=/linuxrc";
            boot_reginfo = "boot_register_node1";
        };
    };
    flash@0 {
        partitions {
            #address-cells = <0x00000002>;
            #size-cells = <0x00000002>;
            ranges;
            partition@0 {
                part_name = "mini-Boot";
                part_offset = <0x00000000 0x00000000>;
                part_size = <0x00000000 0x00100000>;
                part_mask_flags = "RW";
                firmware_crypto = <0x00000000>;
                fs_flags = [00];
                fs_type = [00];
                part_backupOffset = <0xffffffff 0xffffffff>;
            };
            partition@1 {
                part_name = "U-Boot";
                part_offset = <0x00000000 0x00100000>;
                part_size = <0x00000000 0x000c0000>;
                part_mask_flags = "RW";
                firmware_crypto = <0x00000000>;
                fs_flags = [00];
                fs_type = [00];
                part_backupOffset = <0xffffffff 0xffffffff>;
            };
            partition@2 {
                part_name = "smc";
                part_offset = <0x00000000 0x00200000>;
                part_size = <0x00000000 0x00100000>;
                part_mask_flags = "RW";
                firmware_crypto = <0x00000000>;
                fs_flags = "R";
                fs_type = [00];
                part_backupOffset = <0xffffffff 0xffffffff>;
            };
            partition@3 {
                part_name = "updateflag";
                part_offset = <0x00000000 0x00300000>;
                part_size = <0x00000000 0x00100000>;
                part_mask_flags = "RW";
                firmware_crypto = <0x00000000>;
                fs_flags = [00];
                fs_type = [00];
                part_backupOffset = <0xffffffff 0xffffffff>;
            };
            partition@4 {
                part_name = "hwid";
                part_offset = <0x00000000 0x00400000>;
                part_size = <0x00000000 0x00100000>;
                part_mask_flags = "RW";
                firmware_crypto = <0x00000000>;
                fs_flags = [00];
                fs_type = [00];
                part_backupOffset = <0xffffffff 0xffffffff>;
            };
            partition@5 {
                part_name = "dtb";
                part_offset = <0x00000000 0x00500000>;
                part_size = <0x00000000 0x00100000>;
                part_mask_flags = "RW";
                firmware_crypto = <0x00000000>;
                fs_flags = "R";
                fs_type = [00];
                part_backupOffset = <0x00000000 0x00600000>;
            };
            partition@6 {
                part_name = "backdtb";
                part_offset = <0x00000000 0x00600000>;
                part_size = <0x00000000 0x00100000>;
                part_mask_flags = "RW";
                firmware_crypto = <0x00000000>;
                fs_flags = "R";
                fs_type = [00];
                part_backupOffset = <0xffffffff 0xffffffff>;
            };
            partition@7 {
                part_name = "dgs";
                part_offset = <0x00000000 0x00700000>;
                part_size = <0x00000000 0x00100000>;
                part_mask_flags = "RW";
                firmware_crypto = <0x00000000>;
                fs_flags = [00];
                fs_type = [00];
                part_backupOffset = <0xffffffff 0xffffffff>;
            };
            partition@8 {
                part_name = "syslog";
                part_offset = <0x00000000 0x00800000>;
                part_size = <0x00000000 0x00400000>;
                part_mask_flags = "RW";
                firmware_crypto = <0x00000000>;
                fs_flags = "RW";
                fs_type = "ubi";
                part_backupOffset = <0xffffffff 0xffffffff>;
            };
            partition@9 {
                part_name = "config";
                part_offset = <0x00000000 0x00c00000>;
                part_size = <0x00000000 0x00400000>;
                part_mask_flags = "RW";
                firmware_crypto = <0x00000000>;
                fs_flags = "RW";
                fs_type = "ubi";
                part_backupOffset = <0xffffffff 0xffffffff>;
            };
            partition@10 {
                part_name = "backup";
                part_offset = <0x00000000 0x01000000>;
                part_size = <0x00000000 0x00400000>;
                part_mask_flags = "RW";
                firmware_crypto = <0x00000000>;
                fs_flags = "RW";
                fs_type = "ubi";
                part_backupOffset = <0xffffffff 0xffffffff>;
            };
            partition@11 {
                part_name = "appdata";
                part_offset = <0x00000000 0x01400000>;
                part_size = <0x00000000 0x00600000>;
                part_mask_flags = "RW";
                firmware_crypto = <0x00000000>;
                fs_flags = "RW";
                fs_type = "ubi";
                part_backupOffset = <0xffffffff 0xffffffff>;
            };
            partition@12 {
                part_name = "firmware";
                part_offset = <0x00000000 0x01a00000>;
                part_size = <0x00000000 0x02e00000>;
                part_mask_flags = "RW";
                firmware_crypto = <0x00000000>;
                fs_flags = "R";
                fs_type = "squashfs";
                part_backupOffset = <0xffffffff 0xffffffff>;
            };
            partition@13 {
                part_name = "romfs";
                part_offset = <0x00000000 0x04800000>;
                part_size = <0x00000000 0x01e00000>;
                part_mask_flags = "RW";
                firmware_crypto = <0x00000000>;
                fs_flags = "R";
                fs_type = "squashfs";
                part_backupOffset = <0xffffffff 0xffffffff>;
            };
            partition@14 {
                part_name = "Kernel";
                part_offset = <0x00000000 0x06600000>;
                part_size = <0x00000000 0x00700000>;
                part_mask_flags = "RW";
                firmware_crypto = <0x00000001>;
                fs_flags = [00];
                fs_type = [00];
                part_backupOffset = <0xffffffff 0xffffffff>;
            };
            partition@15 {
                part_name = "web";
                part_offset = <0x00000000 0x06d00000>;
                part_size = <0x00000000 0x01000000>;
                part_mask_flags = "RW";
                firmware_crypto = <0x00000000>;
                fs_flags = "R";
                fs_type = "squashfs";
                part_backupOffset = <0xffffffff 0xffffffff>;
            };
            partition@16 {
                part_name = "product";
                part_offset = <0x00000000 0x07d00000>;
                part_size = <0x00000000 0x00300000>;
                part_mask_flags = "RW";
                firmware_crypto = <0x00000000>;
                fs_flags = "R";
                fs_type = "squashfs";
                part_backupOffset = <0xffffffff 0xffffffff>;
            };
        };
    };
    aliases {
        serial0 = "/soc/serial@010a0000";
    };
    memory {
        device_type = "memory";
        reg = <0x10000000 0x10000000>;
    };
    bootpara {
        fd = <0x00000000>;
        debug = <0x00000000>;
        appauto = <0x00000000>;
        dh_keyboard = <0x00000000>;
        ethaddr0 = "0x00";
        ethaddr1 = "0x00";
        lip0 = "0x00";
        lip1 = "0x00";
        id = "0x00";
        hwid = "IPC-HFW3841EP-AS:01:02:02:8F:41:00:01:10:03:01:04:320:03:00:00:00:00:01:00:00:200";
        loglevel = "0x00";
        wifiaddr = "0x00";
        quickstart = <0x00000000>;
    };
    smc-nand {
        vendor = "Fudan-Microxxxxx";
        product = "FM25S01Axxxxxxxx";
        id = <0x000000a1 0x000000e4 0x00000000 0x00000000>;
        id_cnt = <0x00000002>;
        spare_size = <0x00000040>;
        page_size = <0x00000800>;
        page_cnt = <0x00000040>;
        blk_cnt = <0x00000400>;
        plane_cnt = <0x00000001>;
        bits_per_cell = <0x00000001>;
        luns_per_target = <0x00000001>;
        ntargets = <0x00000001>;
        ecc_bitlen = <0x00000001>;
        ecc_perlen = <0x00000200>;
        ecc_addr = <0x000000c0>;
        ecc_bitmask = <0x00000030>;
        ecc_errmask = <0x00000020>;
        rx_width = <0x00000004>;
        tx_width = <0x00000001>;
    };
    reserved-memory {
        #address-cells = <0x00000001>;
        #size-cells = <0x00000001>;
        ranges;
        memlimit {
            reg = <0x17ffe000 0x00002000>;
        };
        logmem {
            reg = <0x17f7e000 0x00080000>;
        };
        dgsmem {
            reg = <0x17f7c000 0x00002000>;
        };
    };
};
